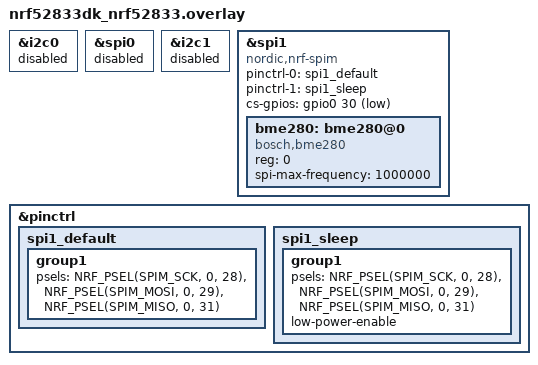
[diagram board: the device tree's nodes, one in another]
/* STEP 2.1 - Add the SPI peripheral to spi1 */
&i2c0 {	status = "disabled";};
&spi0 {	status = "disabled";};
&i2c1 {	status = "disabled";};
	
&spi1 {
    compatible = "nordic,nrf-spim";
	status = "okay";
	pinctrl-0 = <&spi1_default>;
	pinctrl-1 = <&spi1_sleep>;
	pinctrl-names = "default", "sleep";
	cs-gpios = <&gpio0 30 GPIO_ACTIVE_LOW>;
	bme280: bme280@0 {
		compatible = "bosch,bme280";
		reg = <0>;
		spi-max-frequency = <1000000>; 
	};
};

/* STEP 2.2 - Change the pin configuration */
&pinctrl {
	spi1_default: spi1_default {
		group1 {
				psels = <NRF_PSEL(SPIM_SCK, 0, 28)>,
						<NRF_PSEL(SPIM_MOSI, 0, 29)>,
						<NRF_PSEL(SPIM_MISO, 0, 31)>;
		};
	};

	spi1_sleep: spi1_sleep {
		group1 {
				psels = <NRF_PSEL(SPIM_SCK, 0, 28)>,
						<NRF_PSEL(SPIM_MOSI, 0, 29)>,
						<NRF_PSEL(SPIM_MISO, 0, 31)>;
				low-power-enable;
		};
	};
};
